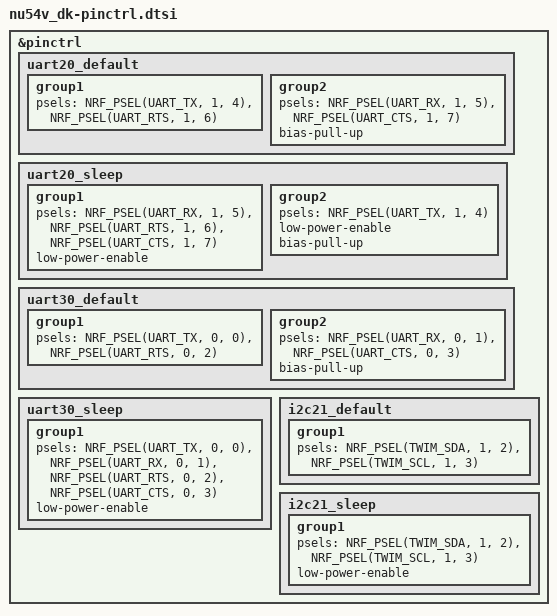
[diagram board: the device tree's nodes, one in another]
/*
 * NU54-DK pin control
 * 핀 번호 근거: hardware/NU54_DK_*_SCH.pdf (docs/02_board_package.md 핀맵 참고)
 */

&pinctrl {
	/* VCOM1 : UARTE_TX/RX/RTS/CTS → DAP(nRF52840) UART2 (SB9~SB12) */
	/omit-if-no-ref/ uart20_default: uart20_default {
		group1 {
			psels = <NRF_PSEL(UART_TX, 1, 4)>,
				<NRF_PSEL(UART_RTS, 1, 6)>;
		};

		group2 {
			psels = <NRF_PSEL(UART_RX, 1, 5)>,
				<NRF_PSEL(UART_CTS, 1, 7)>;
			bias-pull-up;
		};
	};

	/omit-if-no-ref/ uart20_sleep: uart20_sleep {
		group1 {
			psels = <NRF_PSEL(UART_RX, 1, 5)>,
				<NRF_PSEL(UART_RTS, 1, 6)>,
				<NRF_PSEL(UART_CTS, 1, 7)>;
			low-power-enable;
		};

		group2 {
			psels = <NRF_PSEL(UART_TX, 1, 4)>;
			low-power-enable;
			bias-pull-up;
		};
	};

	/* VCOM0 : LPUART_TX/RX/RTS/CTS → DAP(nRF52840) UART (SB5~SB8) */
	/omit-if-no-ref/ uart30_default: uart30_default {
		group1 {
			psels = <NRF_PSEL(UART_TX, 0, 0)>,
				<NRF_PSEL(UART_RTS, 0, 2)>;
		};

		group2 {
			psels = <NRF_PSEL(UART_RX, 0, 1)>,
				<NRF_PSEL(UART_CTS, 0, 3)>;
			bias-pull-up;
		};
	};

	/omit-if-no-ref/ uart30_sleep: uart30_sleep {
		group1 {
			psels = <NRF_PSEL(UART_TX, 0, 0)>,
				<NRF_PSEL(UART_RX, 0, 1)>,
				<NRF_PSEL(UART_RTS, 0, 2)>,
				<NRF_PSEL(UART_CTS, 0, 3)>;
			low-power-enable;
		};
	};

	/* Qwiic(J5) / PMIC(BQ25186) I2C : P1.02 SDA, P1.03 SCL (SB14~SB17) */
	/omit-if-no-ref/ i2c21_default: i2c21_default {
		group1 {
			psels = <NRF_PSEL(TWIM_SDA, 1, 2)>,
				<NRF_PSEL(TWIM_SCL, 1, 3)>;
		};
	};

	/omit-if-no-ref/ i2c21_sleep: i2c21_sleep {
		group1 {
			psels = <NRF_PSEL(TWIM_SDA, 1, 2)>,
				<NRF_PSEL(TWIM_SCL, 1, 3)>;
			low-power-enable;
		};
	};
};
